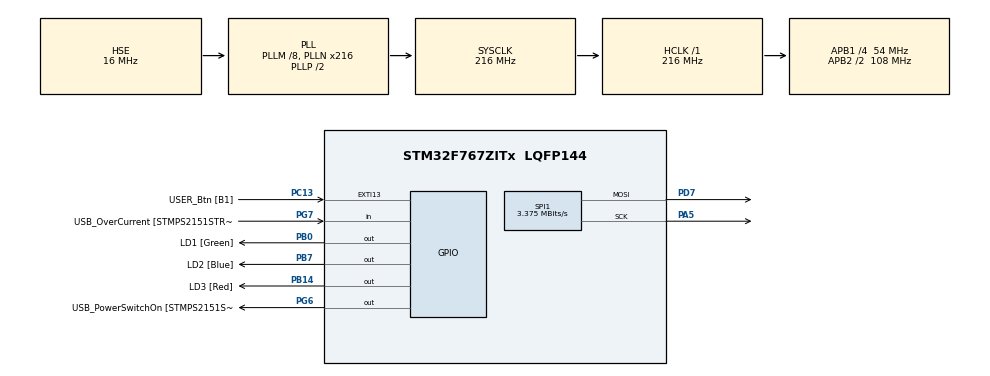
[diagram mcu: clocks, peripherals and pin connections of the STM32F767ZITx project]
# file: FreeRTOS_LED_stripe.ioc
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Dma.Request0=SPI1_TX
Dma.SPI1_TX.0.Direction=DMA_MEMORY_TO_PERIPH
Dma.SPI1_TX.0.FIFOMode=DMA_FIFOMODE_DISABLE
Dma.SPI1_TX.0.Instance=DMA2_Stream3
Dma.SPI1_TX.0.MemDataAlignment=DMA_MDATAALIGN_BYTE
Dma.SPI1_TX.0.MemInc=DMA_MINC_ENABLE
Dma.SPI1_TX.0.Mode=DMA_NORMAL
Dma.SPI1_TX.0.PeriphDataAlignment=DMA_PDATAALIGN_BYTE
Dma.SPI1_TX.0.PeriphInc=DMA_PINC_DISABLE
Dma.SPI1_TX.0.Priority=DMA_PRIORITY_LOW
FREERTOS.Tasks01=defaultTask,24,128,StartDefaultTask,Default,NULL,Dynamic,NULL,NULL;LEDStripeTask,24,256,StartLEDStripeTask,Default,NULL,Dynamic,NULL,NULL
FREERTOS.configUSE_NEWLIB_REENTRANT=1
Mcu.Family=STM32F7
Mcu.Name=STM32F767ZITx
Mcu.Package=LQFP144
NVIC.DMA2_Stream3_IRQn=true\:0\:0\:false\:false\:true\:false\:false\:true\:true
NVIC.PriorityGroup=NVIC_PRIORITYGROUP_4
NVIC.TIM6_DAC_IRQn=true\:15\:0\:false\:false\:true\:false\:false\:true\:true
NVIC.TimeBase=TIM6_DAC_IRQn
NVIC.TimeBaseIP=TIM6
PA1.GPIO_Label=RMII_REF_CLK [LAN8742A-CZ-TR_REFCLK0]
PA1.Signal=ETH_REF_CLK
PA10.GPIO_Label=USB_ID
PA10.Signal=USB_OTG_FS_ID
PA11.GPIO_Label=USB_DM
PA11.Signal=USB_OTG_FS_DM
PA12.GPIO_Label=USB_DP
PA12.Signal=USB_OTG_FS_DP
PA13.GPIO_Label=TMS
PA13.Signal=SYS_JTMS-SWDIO
PA14.GPIO_Label=TCK
PA14.Signal=SYS_JTCK-SWCLK
PA2.GPIO_Label=RMII_MDIO [LAN8742A-CZ-TR_MDIO]
PA2.Signal=ETH_MDIO
PA5.Mode=TX_Only_Simplex_Unidirect_Master
PA5.Signal=SPI1_SCK
PA7.GPIO_Label=RMII_CRS_DV [LAN8742A-CZ-TR_CRS_DV]
PA7.Signal=ETH_CRS_DV
PA8.GPIO_Label=USB_SOF [TP1]
PA8.Signal=USB_OTG_FS_SOF
PA9.GPIO_Label=USB_VBUS
PA9.Signal=USB_OTG_FS_VBUS
PB0.GPIO_Label=LD1 [Green]
PB0.Signal=GPIO_Output
PB13.GPIO_Label=RMII_TXD1 [LAN8742A-CZ-TR_TXD1]
PB13.Signal=ETH_TXD1
PB14.GPIO_Label=LD3 [Red]
PB14.Signal=GPIO_Output
PB3.GPIO_Label=SW0
PB3.Signal=SYS_JTDO-SWO
PB7.GPIO_Label=LD2 [Blue]
PB7.Signal=GPIO_Output
PC1.GPIO_Label=RMII_MDC [LAN8742A-CZ-TR_MDC]
PC1.Signal=ETH_MDC
PC13.GPIO_Label=USER_Btn [B1]
PC13.Signal=GPXTI13
PC14/OSC32_IN.Signal=RCC_OSC32_IN
PC15/OSC32_OUT.Signal=RCC_OSC32_OUT
PC4.GPIO_Label=RMII_RXD0 [LAN8742A-CZ-TR_RXD0]
PC4.Signal=ETH_RXD0
PC5.GPIO_Label=RMII_RXD1 [LAN8742A-CZ-TR_RXD1]
PC5.Signal=ETH_RXD1
PD7.Mode=TX_Only_Simplex_Unidirect_Master
PD7.Signal=SPI1_MOSI
PD8.GPIO_Label=STLK_RX [STM32F103CBT6_PA3]
PD8.Signal=USART3_TX
PD9.GPIO_Label=STLK_TX [STM32F103CBT6_PA2]
PD9.Signal=USART3_RX
PG11.GPIO_Label=RMII_TX_EN [LAN8742A-CZ-TR_TXEN]
PG11.Signal=ETH_TX_EN
PG13.GPIO_Label=RMII_TXD0 [LAN8742A-CZ-TR_TXD0]
PG13.Signal=ETH_TXD0
PG6.GPIO_Label=USB_PowerSwitchOn [STMPS2151STR_EN]
PG6.Signal=GPIO_Output
PG7.GPIO_Label=USB_OverCurrent [STMPS2151STR_FAULT]
PG7.Signal=GPIO_Input
PH0/OSC_IN.GPIO_Label=MCO [STM32F103CBT6_PA8]
PH0/OSC_IN.Mode=HSE-External-Oscillator
PH0/OSC_IN.Signal=RCC_OSC_IN
PH1/OSC_OUT.Mode=HSE-External-Oscillator
PH1/OSC_OUT.Signal=RCC_OSC_OUT
ProjectManager.HeapSize=0x200
ProjectManager.StackSize=0x400
ProjectManager.TargetToolchain=STM32CubeIDE
RCC.48MHZClocksFreq_Value=24000000
RCC.AHBFreq_Value=216000000
RCC.APB1CLKDivider=RCC_HCLK_DIV4
RCC.APB1Freq_Value=54000000
RCC.APB1TimFreq_Value=108000000
RCC.APB2CLKDivider=RCC_HCLK_DIV2
RCC.APB2Freq_Value=108000000
RCC.APB2TimFreq_Value=216000000
RCC.CortexFreq_Value=216000000
RCC.HCLKFreq_Value=216000000
RCC.HSE_VALUE=16000000
RCC.HSI_VALUE=16000000
RCC.LSE_VALUE=32768
RCC.PLLM=8
RCC.PLLMUL=RCC_PLL_MUL9
RCC.PLLN=216
RCC.PLLSourceVirtual=RCC_PLLSOURCE_HSE
RCC.PRESCALERUSB=RCC_USBCLKSOURCE_PLL_DIV1_5
RCC.SYSCLKFreq_VALUE=216000000
RCC.SYSCLKSource=RCC_SYSCLKSOURCE_PLLCLK
RCC.SYSCLKSourceVirtual=RCC_SYSCLKSOURCE_PLLCLK
RCC.USBFreq_Value=216000000
RCC.VCOOutputFreq_Value=432000000
SPI1.BaudRatePrescaler=SPI_BAUDRATEPRESCALER_32
SPI1.CalculateBaudRate=3.375 MBits/s
SPI1.DataSize=SPI_DATASIZE_8BIT
SPI1.Direction=SPI_DIRECTION_2LINES
SPI1.Mode=SPI_MODE_MASTER
SPI1.NSSPMode=SPI_NSS_PULSE_DISABLE
SPI1.VirtualType=VM_MASTER
VP_FREERTOS_VS_CMSIS_V2.Mode=CMSIS_V2
VP_SYS_VS_tim6.Mode=TIM6
board=NUCLEO-F767ZI

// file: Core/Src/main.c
/* USER CODE BEGIN Header */
/**
  ******************************************************************************
  * @file           : main.c
  * @brief          : Main program body
  ******************************************************************************
  * @attention
  *
  * Copyright (c) 2024 STMicroelectronics.
  * All rights reserved.
  *
  * This software is licensed under terms that can be found in the LICENSE file
  * in the root directory of this software component.
  * If no LICENSE file comes with this software, it is provided AS-IS.
  *
  ******************************************************************************
  */
/* USER CODE END Header */
#include "main.h"
#include "cmsis_os.h"
#include "dma.h"
#include "spi.h"
#include "gpio.h"

/* USER CODE BEGIN Includes */
#include "ws281x.h"

/* USER CODE END Includes */

void SystemClock_Config(void);
void MX_FREERTOS_Init(void);

/* USER CODE BEGIN 0 */
ws281x_t pixel;

/* USER CODE END 0 */

int main(void)
{

  /* MCU Configuration--------------------------------------------------------*/

  /* Reset of all peripherals, Initializes the Flash interface and the Systick. */
  HAL_Init();

  /* Configure the system clock */
  SystemClock_Config();

  /* Initialize all configured peripherals */
  MX_GPIO_Init();
  MX_DMA_Init();
  MX_SPI1_Init();

  /* Init scheduler */
  osKernelInitialize();  /* Call init function for freertos objects (in freertos.c) */
  MX_FREERTOS_Init();

  /* Start scheduler */
  osKernelStart();

  /* We should never get here as control is now taken by the scheduler */
  /* Infinite loop */
  while (1)
  {

  }
}

void SystemClock_Config(void)
{
  RCC_OscInitTypeDef RCC_OscInitStruct = {0};
  RCC_ClkInitTypeDef RCC_ClkInitStruct = {0};

  /** Configure the main internal regulator output voltage
  */
  __HAL_RCC_PWR_CLK_ENABLE();
  __HAL_PWR_VOLTAGESCALING_CONFIG(PWR_REGULATOR_VOLTAGE_SCALE1);

  /** Initializes the RCC Oscillators according to the specified parameters
  * in the RCC_OscInitTypeDef structure.
  */
  RCC_OscInitStruct.OscillatorType = RCC_OSCILLATORTYPE_HSE;
  RCC_OscInitStruct.HSEState = RCC_HSE_ON;
  RCC_OscInitStruct.PLL.PLLState = RCC_PLL_ON;
  RCC_OscInitStruct.PLL.PLLSource = RCC_PLLSOURCE_HSE;
  RCC_OscInitStruct.PLL.PLLM = 8;
  RCC_OscInitStruct.PLL.PLLN = 216;
  RCC_OscInitStruct.PLL.PLLP = RCC_PLLP_DIV2;
  RCC_OscInitStruct.PLL.PLLQ = 2;
  RCC_OscInitStruct.PLL.PLLR = 2;
  if (HAL_RCC_OscConfig(&RCC_OscInitStruct) != HAL_OK)
  {
    Error_Handler();
  }

  /** Activate the Over-Drive mode
  */
  if (HAL_PWREx_EnableOverDrive() != HAL_OK)
  {
    Error_Handler();
  }

  /** Initializes the CPU, AHB and APB buses clocks
  */
  RCC_ClkInitStruct.ClockType = RCC_CLOCKTYPE_HCLK|RCC_CLOCKTYPE_SYSCLK
                              |RCC_CLOCKTYPE_PCLK1|RCC_CLOCKTYPE_PCLK2;
  RCC_ClkInitStruct.SYSCLKSource = RCC_SYSCLKSOURCE_PLLCLK;
  RCC_ClkInitStruct.AHBCLKDivider = RCC_SYSCLK_DIV1;
  RCC_ClkInitStruct.APB1CLKDivider = RCC_HCLK_DIV4;
  RCC_ClkInitStruct.APB2CLKDivider = RCC_HCLK_DIV2;

  if (HAL_RCC_ClockConfig(&RCC_ClkInitStruct, FLASH_LATENCY_7) != HAL_OK)
  {
    Error_Handler();
  }
}

void HAL_TIM_PeriodElapsedCallback(TIM_HandleTypeDef *htim)
{
  if (htim->Instance == TIM6) {
    HAL_IncTick();
  }
}

void Error_Handler(void)
{
  __disable_irq();
  while (1)
  {
  }
}

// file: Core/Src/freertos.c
/* USER CODE BEGIN Header */
/**
  ******************************************************************************
  * File Name          : freertos.c
  * Description        : Code for freertos applications
  ******************************************************************************
  * @attention
  *
  * Copyright (c) 2024 STMicroelectronics.
  * All rights reserved.
  *
  * This software is licensed under terms that can be found in the LICENSE file
  * in the root directory of this software component.
  * If no LICENSE file comes with this software, it is provided AS-IS.
  *
  ******************************************************************************
  */
/* USER CODE END Header */

#include "FreeRTOS.h"
#include "task.h"
#include "main.h"
#include "cmsis_os.h"

/* USER CODE BEGIN Includes */
#include "ws281x.h"

/* USER CODE END Includes */

/* USER CODE BEGIN Variables */
extern ws281x_t pixel;
extern SPI_HandleTypeDef hspi1;

/* USER CODE END Variables */
/* Definitions for defaultTask */
osThreadId_t defaultTaskHandle;
const osThreadAttr_t defaultTask_attributes = {
  .name = "defaultTask",
  .stack_size = 128 * 4,
  .priority = (osPriority_t) osPriorityNormal,
};
/* Definitions for LEDStripeTask */
osThreadId_t LEDStripeTaskHandle;
const osThreadAttr_t LEDStripeTask_attributes = {
  .name = "LEDStripeTask",
  .stack_size = 256 * 4,
  .priority = (osPriority_t) osPriorityNormal,
};

void StartDefaultTask(void *argument);
void StartLEDStripeTask(void *argument);

void MX_FREERTOS_Init(void); /* (MISRA C 2004 rule 8.1) */

void MX_FREERTOS_Init(void) {

  /* Create the thread(s) */
  /* creation of defaultTask */
  defaultTaskHandle = osThreadNew(StartDefaultTask, NULL, &defaultTask_attributes);

  /* creation of LEDStripeTask */
  LEDStripeTaskHandle = osThreadNew(StartLEDStripeTask, NULL, &LEDStripeTask_attributes);

}

void StartDefaultTask(void *argument)
{
  for(;;)
  {
    osDelay(1);
  }
}

/* USER CODE BEGIN Header_StartLEDStripeTask */
/**
* @brief Function implementing the LEDStripeTask thread.
* @param argument: Not used
* @retval None
*/
// 7 * 3 * 35 = 735 bytes heap usage

/* USER CODE END Header_StartLEDStripeTask */
void StartLEDStripeTask(void *argument)
{
  /* USER CODE BEGIN StartLEDStripeTask */
	ws281x_init(&pixel, &hspi1, 21, ws281x_order_grb);
	ws281x_test_slow(&pixel);

  /* Infinite loop */
  for(;;)
  {
    osDelay(1);
  }
  /* USER CODE END StartLEDStripeTask */
}
